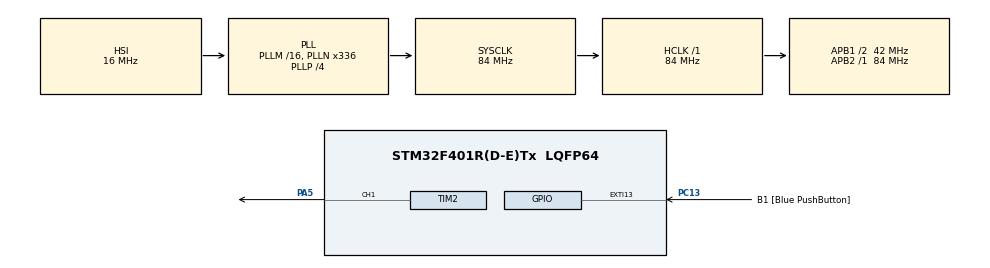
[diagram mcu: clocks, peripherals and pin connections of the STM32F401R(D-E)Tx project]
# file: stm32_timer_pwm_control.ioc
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Mcu.Family=STM32F4
Mcu.Name=STM32F401R(D-E)Tx
Mcu.Package=LQFP64
NVIC.EXTI15_10_IRQn=true\:0\:0\:false\:false\:true\:true\:true\:true
NVIC.PriorityGroup=NVIC_PRIORITYGROUP_4
NVIC.TIM2_IRQn=true\:0\:0\:false\:false\:true\:true\:true\:true
PA5.Signal=S_TIM2_CH1_ETR
PC13-ANTI_TAMP.GPIO_Label=B1 [Blue PushButton]
PC13-ANTI_TAMP.GPIO_ModeDefaultEXTI=GPIO_MODE_IT_FALLING
PC13-ANTI_TAMP.GPIO_PuPd=GPIO_NOPULL
PC13-ANTI_TAMP.Signal=GPXTI13
PH0\ -\ OSC_IN.Mode=HSE-External-Clock-Source
PH0\ -\ OSC_IN.Signal=RCC_OSC_IN
PH1\ -\ OSC_OUT.Mode=HSE-External-Clock-Source
PH1\ -\ OSC_OUT.Signal=RCC_OSC_OUT
ProjectManager.HeapSize=0x200
ProjectManager.StackSize=0x400
ProjectManager.TargetToolchain=STM32CubeIDE
RCC.48MHZClocksFreq_Value=48000000
RCC.AHBFreq_Value=84000000
RCC.APB1CLKDivider=RCC_HCLK_DIV2
RCC.APB1Freq_Value=42000000
RCC.APB1TimFreq_Value=84000000
RCC.APB2Freq_Value=84000000
RCC.APB2TimFreq_Value=84000000
RCC.CortexFreq_Value=84000000
RCC.HCLKFreq_Value=84000000
RCC.HSE_VALUE=8000000
RCC.HSI_VALUE=16000000
RCC.PLLN=336
RCC.PLLP=RCC_PLLP_DIV4
RCC.PLLQ=7
RCC.SYSCLKFreq_VALUE=84000000
RCC.SYSCLKSource=RCC_SYSCLKSOURCE_PLLCLK
RCC.VCOOutputFreq_Value=336000000
SH.S_TIM2_CH1_ETR.0=TIM2_CH1,PWM Generation1 CH1
TIM2.Channel-PWM\ Generation1\ CH1=TIM_CHANNEL_1
TIM2.Period=999
TIM2.Prescaler=8399
VP_TIM2_VS_ClockSourceINT.Mode=Internal
board=NUCLEO-F401RE

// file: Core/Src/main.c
/* USER CODE BEGIN Header */
/**
  ******************************************************************************
  * @file           : main.c
  * @brief          : Main program body
  ******************************************************************************
  * @attention
  *
  * Copyright (c) 2026 STMicroelectronics.
  * All rights reserved.
  *
  * This software is licensed under terms that can be found in the LICENSE file
  * in the root directory of this software component.
  * If no LICENSE file comes with this software, it is provided AS-IS.
  *
  ******************************************************************************
  */
/* USER CODE END Header */
#include "main.h"

/* USER CODE BEGIN PD */
#define PWM_ARR         (999U)   // ARR=999 => 1000 counts
#define DUTY_10_CCR     (100U)   // 10%
#define DUTY_50_CCR     (500U)   // 50%
#define DUTY_90_CCR     (900U)   // 90%
/* USER CODE END PD */

TIM_HandleTypeDef htim2;

/* USER CODE BEGIN PV */
static volatile uint8_t g_duty_state = 0; // 0:10%, 1:50%, 2:90%
/* USER CODE END PV */

void SystemClock_Config(void);
static void MX_GPIO_Init(void);
static void MX_TIM2_Init(void);
/* USER CODE BEGIN PFP */
static void PWM_SetDutyCCR(uint32_t ccr);
/* USER CODE END PFP */

/* USER CODE BEGIN 0 */

/**
  * @brief PWM 듀티를 CCR로 설정
  * @note  듀티(%) = CCR / (ARR+1) * 100
  */
static void PWM_SetDutyCCR(uint32_t ccr)
{
  if (ccr > PWM_ARR) ccr = PWM_ARR;
  __HAL_TIM_SET_COMPARE(&htim2, TIM_CHANNEL_1, ccr);
}

/**
  * @brief USER 버튼(PC13) EXTI 콜백
  *        누를 때마다 듀티 10% -> 50% -> 90% -> 반복
  */
void HAL_GPIO_EXTI_Callback(uint16_t GPIO_Pin)
{
  if (GPIO_Pin == B1_Pin)
  {
    if (g_duty_state == 0)
    {
      PWM_SetDutyCCR(DUTY_10_CCR);
      g_duty_state = 1;
    }
    else if (g_duty_state == 1)
    {
      PWM_SetDutyCCR(DUTY_50_CCR);
      g_duty_state = 2;
    }
    else
    {
      PWM_SetDutyCCR(DUTY_90_CCR);
      g_duty_state = 0;
    }
  }
}

/* USER CODE END 0 */

int main(void)
{
  /* MCU Configuration--------------------------------------------------------*/
  HAL_Init();
  SystemClock_Config();

  /* Initialize all configured peripherals */
  MX_GPIO_Init();
  MX_TIM2_Init();

  /* USER CODE BEGIN 2 */
  // 1) PWM 시작 (이게 없으면 출력 안 나옴)
  if (HAL_TIM_PWM_Start(&htim2, TIM_CHANNEL_1) != HAL_OK)
  {
    Error_Handler();
  }

  // 2) 초기 듀티 설정(예: 50%)
  PWM_SetDutyCCR(DUTY_50_CCR);
  g_duty_state = 2; // 다음 버튼 누르면 90%로 가게 하고 싶으면 상태 조절 가능
  /* USER CODE END 2 */

  /* Infinite loop */
  while (1)
  {
    // 메인 루프는 비워둠: PWM은 하드웨어가 계속 출력
    // 버튼 이벤트가 들어오면 EXTI 콜백에서 CCR만 바꿔 듀티 변경
  }
}

void SystemClock_Config(void)
{
  RCC_OscInitTypeDef RCC_OscInitStruct = {0};
  RCC_ClkInitTypeDef RCC_ClkInitStruct = {0};

  __HAL_RCC_PWR_CLK_ENABLE();
  __HAL_PWR_VOLTAGESCALING_CONFIG(PWR_REGULATOR_VOLTAGE_SCALE2);

  RCC_OscInitStruct.OscillatorType = RCC_OSCILLATORTYPE_HSI;
  RCC_OscInitStruct.HSIState = RCC_HSI_ON;
  RCC_OscInitStruct.HSICalibrationValue = RCC_HSICALIBRATION_DEFAULT;
  RCC_OscInitStruct.PLL.PLLState = RCC_PLL_ON;
  RCC_OscInitStruct.PLL.PLLSource = RCC_PLLSOURCE_HSI;
  RCC_OscInitStruct.PLL.PLLM = 16;
  RCC_OscInitStruct.PLL.PLLN = 336;
  RCC_OscInitStruct.PLL.PLLP = RCC_PLLP_DIV4;
  RCC_OscInitStruct.PLL.PLLQ = 7;
  if (HAL_RCC_OscConfig(&RCC_OscInitStruct) != HAL_OK)
  {
    Error_Handler();
  }

  RCC_ClkInitStruct.ClockType = RCC_CLOCKTYPE_HCLK|RCC_CLOCKTYPE_SYSCLK
                              |RCC_CLOCKTYPE_PCLK1|RCC_CLOCKTYPE_PCLK2;
  RCC_ClkInitStruct.SYSCLKSource = RCC_SYSCLKSOURCE_PLLCLK;
  RCC_ClkInitStruct.AHBCLKDivider = RCC_SYSCLK_DIV1;
  RCC_ClkInitStruct.APB1CLKDivider = RCC_HCLK_DIV2;
  RCC_ClkInitStruct.APB2CLKDivider = RCC_HCLK_DIV1;

  if (HAL_RCC_ClockConfig(&RCC_ClkInitStruct, FLASH_LATENCY_2) != HAL_OK)
  {
    Error_Handler();
  }
}

static void MX_TIM2_Init(void)
{
  TIM_ClockConfigTypeDef sClockSourceConfig = {0};
  TIM_MasterConfigTypeDef sMasterConfig = {0};
  TIM_OC_InitTypeDef sConfigOC = {0};

  htim2.Instance = TIM2;
  htim2.Init.Prescaler = 83;
  htim2.Init.CounterMode = TIM_COUNTERMODE_UP;
  htim2.Init.Period = PWM_ARR; // 999
  htim2.Init.ClockDivision = TIM_CLOCKDIVISION_DIV1;
  htim2.Init.AutoReloadPreload = TIM_AUTORELOAD_PRELOAD_DISABLE;

  if (HAL_TIM_Base_Init(&htim2) != HAL_OK)
  {
    Error_Handler();
  }
  sClockSourceConfig.ClockSource = TIM_CLOCKSOURCE_INTERNAL;
  if (HAL_TIM_ConfigClockSource(&htim2, &sClockSourceConfig) != HAL_OK)
  {
    Error_Handler();
  }
  if (HAL_TIM_PWM_Init(&htim2) != HAL_OK)
  {
    Error_Handler();
  }
  sMasterConfig.MasterOutputTrigger = TIM_TRGO_RESET;
  sMasterConfig.MasterSlaveMode = TIM_MASTERSLAVEMODE_DISABLE;
  if (HAL_TIMEx_MasterConfigSynchronization(&htim2, &sMasterConfig) != HAL_OK)
  {
    Error_Handler();
  }

  sConfigOC.OCMode = TIM_OCMODE_PWM1;

  // CubeMX에선 Pulse=0으로 생성돼도, 우리는 main에서 CCR을 세팅할 거라 0으로 둬도 됨.
  // 그래도 보기 좋게 초기 50%를 넣고 싶으면 500U로 바꿔도 됨.
  sConfigOC.Pulse = 0;

  sConfigOC.OCPolarity = TIM_OCPOLARITY_HIGH;
  sConfigOC.OCFastMode = TIM_OCFAST_DISABLE;
  if (HAL_TIM_PWM_ConfigChannel(&htim2, &sConfigOC, TIM_CHANNEL_1) != HAL_OK)
  {
    Error_Handler();
  }

  HAL_TIM_MspPostInit(&htim2);
}

static void MX_GPIO_Init(void)
{
  GPIO_InitTypeDef GPIO_InitStruct = {0};

  __HAL_RCC_GPIOC_CLK_ENABLE();
  __HAL_RCC_GPIOH_CLK_ENABLE();
  __HAL_RCC_GPIOA_CLK_ENABLE();

  /*Configure GPIO pin : B1_Pin */
  GPIO_InitStruct.Pin = B1_Pin;
  GPIO_InitStruct.Mode = GPIO_MODE_IT_FALLING;
  GPIO_InitStruct.Pull = GPIO_NOPULL;
  HAL_GPIO_Init(B1_GPIO_Port, &GPIO_InitStruct);

  /* EXTI interrupt init*/
  HAL_NVIC_SetPriority(EXTI15_10_IRQn, 0, 0);
  HAL_NVIC_EnableIRQ(EXTI15_10_IRQn);
}

void Error_Handler(void)
{
  __disable_irq();
  while (1)
  {
  }
}
